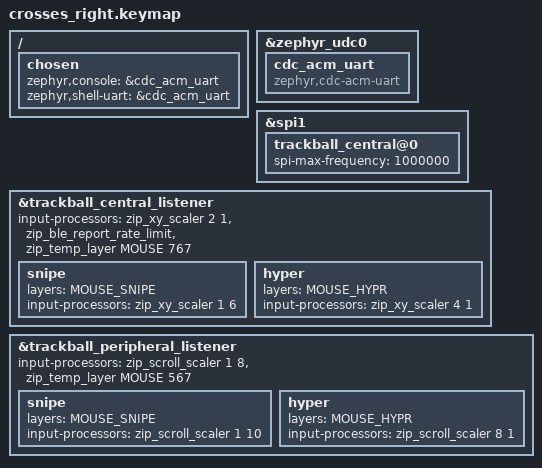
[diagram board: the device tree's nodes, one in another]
#include "crosses_shared.dtsi"
#include <dt-bindings/zmk/input_transform.h>
#include <input/processors.dtsi>

/ {
    chosen {
        zephyr,console = &cdc_acm_uart;
        zephyr,shell-uart = &cdc_acm_uart;
    };
};

&zephyr_udc0 {
    cdc_acm_uart: cdc_acm_uart {
        compatible = "zephyr,cdc-acm-uart";
    };
};

&spi1 {
    trackball_central@0 {
        spi-max-frequency = <1000000>;
    };
};

&trackball_central_listener {
    input-processors = <&zip_xy_scaler 2 1>, <&zip_ble_report_rate_limit>, <&zip_temp_layer MOUSE 767>;

    snipe {
        layers = <MOUSE_SNIPE>;
        input-processors = <&zip_xy_scaler 1 6>;
    };

    hyper {
        layers = <MOUSE_HYPR>;
        input-processors = <&zip_xy_scaler 4 1>;
    };
};

&trackball_peripheral_listener {
    input-processors = <&zip_scroll_scaler 1 8>, <&zip_temp_layer MOUSE 567>;

    snipe {
        layers = <MOUSE_SNIPE>;
        input-processors = <&zip_scroll_scaler 1 10>;
    };

    hyper {
        layers = <MOUSE_HYPR>;
        input-processors = <&zip_scroll_scaler 8 1>;
    };
};
